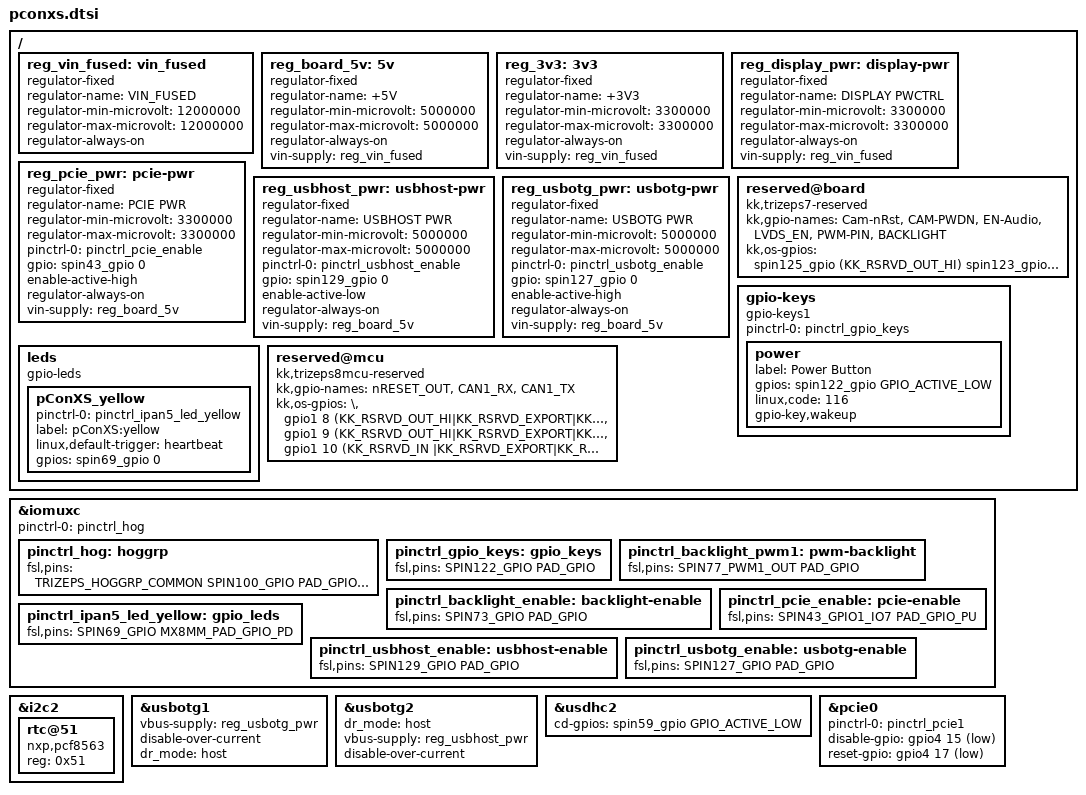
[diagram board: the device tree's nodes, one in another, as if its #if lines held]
/*
 * Copyright 2020 Keith & Koep GmbH
 *
 */

/*
Remarks:
    The main device-tree difference between pConXS V1 and V2 is, that pConXS features:
    - a switch to enable pcie-power
    - 1GBit Ethernet. Use ETHERNET_ONLY_100MBIT define for pConXS V1!

Defines:
    PCONXS_NOT_USE_PCIE_PWR         SPIN113 is used on pConXS V2 to switch power. Since this pin is not connected on V1 no need to actually set this.
	PCONXS_V1 on pConXS V1 pcie-power can not be switched separately but
	          3V3_AUX can be switched by SPIN43 aka. GPIO1_OI7
*/

#define NOBACKLIGHT_PWM         1

&iomuxc {

	pinctrl-names = "default";
	pinctrl-0 = <&pinctrl_hog>;

        pinctrl_hog: hoggrp {
		fsl,pins = < 
					 TRIZEPS_HOGGRP_COMMON
					 SPIN100_GPIO           PAD_GPIO_PU   /* LVDS    EN  SODIMM Pin 110 gpio 1.05=005 */
					 SPIN102_GPIO  		PAD_GPIO_PU   /* Audio Amp                                */
		    		         SPIN123_GPIO		PAD_GPIO_PU   /* Camera Pwdn SODIMM Pin 123               */
   					 SPIN125_GPIO		PAD_GPIO_PU   /* Camera nRST SODIMM Pin 125               */
   					 SPIN114_GPIO		PAD_GPIO_PU   /* BL EN(LVDS) SODIMM Pin 114 gpio 4.14=110 */
#ifndef NOBACKLIGHT_PWM					 
					 SPIN77_GPIO             PAD_GPIO_PU   /* Gpio PWM */
#endif					 
		       >;
	};

#if !defined (__DTS_TRIZEPS8NANO_PINFUNC_H)
        pinctrl_gpio_keys: gpio_keys {
		fsl,pins = < SPIN122_GPIO       PAD_GPIO >;  /* PowerButton SODIMM Pin 122 */
	};
#endif        

#ifndef NOBACKLIGHT
	pinctrl_backlight_pwm1: pwm-backlight {
		fsl,pins = < SPIN77_PWM1_OUT	PAD_GPIO >;	/* BACKLIGHT_PWM */
	};
#endif

	pinctrl_backlight_enable: backlight-enable {
		fsl,pins = < SPIN73_GPIO	    PAD_GPIO 	/* BACKLIGHT_ENABLE SODIMM Pin 73 */
			   >;
#if 0
                             SPIN114 for LVDS Backlight init via HOG 
/* 		             SPIN114_GPIO           PAD_GPIO_PU /* BACKLIGHT_ENABLE SODIMM Pin 114 gpio 4.14=110 */
#endif			   
	};

#if 1 //!defined (PCONXS_NOT_USE_PCIE_PWR) || (PCONXS_NOT_USE_PCIE_PWR==0)
	pinctrl_pcie_enable: pcie-enable 	{
#ifdef PCONXS_V1
		fsl,pins = < SPIN43_GPIO1_IO7   PAD_GPIO_PU >;
#else
		fsl,pins = < SPIN113_GPIO       PAD_GPIO_PU >; /* USBH_PWR SODIMM Pin 113 */
#endif
	};
#endif

	pinctrl_ipan5_led_yellow: gpio_leds
	{
		fsl,pins = <SPIN69_GPIO MX8MM_PAD_GPIO_PD>;  /* Heartbeat LED gpio5.2 SODIMM Pin 69 J12-9 */
	};

	pinctrl_usbhost_enable: usbhost-enable 	{
		fsl,pins = < SPIN129_GPIO		PAD_GPIO >; /* USBH_PWR */
	};

	pinctrl_usbotg_enable: usbotg-enable 	{
		fsl,pins = < SPIN127_GPIO		PAD_GPIO >; /* USBOTG_PWR */
	};		
};

/ {
	reg_vin_fused: vin_fused {
		compatible = "regulator-fixed";
		regulator-name = "VIN_FUSED";
		regulator-min-microvolt = <12000000>;
		/* max	should be 24V but the fixed regulator driver does
		not allow a range here */
		regulator-max-microvolt = <12000000>;
		regulator-always-on;
	};

	reg_board_5v: 5v {
		compatible = "regulator-fixed";
		regulator-name = "+5V";
		regulator-min-microvolt = <5000000>;
		regulator-max-microvolt = <5000000>;
		regulator-always-on;
		vin-supply = <&reg_vin_fused>;
	};

	reg_3v3: 3v3 {
		compatible = "regulator-fixed";
		regulator-name = "+3V3";
		regulator-min-microvolt = <3300000>;
		regulator-max-microvolt = <3300000>;
		regulator-always-on;
		vin-supply = <&reg_vin_fused>;
	};

    reg_display_pwr: display-pwr {
		compatible = "regulator-fixed";
		regulator-name = "DISPLAY PWCTRL";
		regulator-min-microvolt = <3300000>;
		regulator-max-microvolt = <3300000>;
		regulator-always-on;
		vin-supply = <&reg_vin_fused>;
	};

#if 1 //!defined (PCONXS_NOT_USE_PCIE_PWR) || (PCONXS_NOT_USE_PCIE_PWR==0)
	reg_pcie_pwr: pcie-pwr {
		compatible = "regulator-fixed";
		regulator-name = "PCIE PWR";
		regulator-min-microvolt = <3300000>;
		regulator-max-microvolt = <3300000>;
		pinctrl-names = "default";
		pinctrl-0 = <&pinctrl_pcie_enable>;
#ifdef PCONXS_V1
		gpio = <spin43_gpio 0>;
#else
		gpio = <spin113_gpio 0>;
#endif    
		enable-active-high;
		regulator-always-on;
		vin-supply = <&reg_board_5v>;
	};
#endif    

	reg_usbhost_pwr: usbhost-pwr {
		compatible = "regulator-fixed";
		regulator-name = "USBHOST PWR";
		regulator-min-microvolt = <5000000>;
		regulator-max-microvolt = <5000000>;
		pinctrl-names = "default";
		pinctrl-0 = <&pinctrl_usbhost_enable>;
		gpio = <spin129_gpio 0>;
		enable-active-low;
		regulator-always-on;
		vin-supply = <&reg_board_5v>;
	};

	reg_usbotg_pwr: usbotg-pwr {
		compatible = "regulator-fixed";
		regulator-name = "USBOTG PWR";
		regulator-min-microvolt = <5000000>;
		regulator-max-microvolt = <5000000>;
		pinctrl-names = "default";
		pinctrl-0 = <&pinctrl_usbotg_enable>;
		gpio = <spin127_gpio 0>;
#if defined(PCONXS_III_OTG_ACTIVE_HIGH) && (PCONXS_III_OTG_ACTIVE_HIGH==1)
		enable-active-high;
#else
		enable-active-low;
#endif
		regulator-always-on;
		vin-supply = <&reg_board_5v>;
	};

  	reserved@board {
        compatible      = "kk,trizeps7-reserved";
#if NOBACKLIGHT_PWM			    	
        kk,gpio-names   = "Cam-nRst","CAM-PWDN","EN-Audio","LVDS_EN", "PWM-PIN", "BACKLIGHT";
#else
        kk,gpio-names   = "Cam-nRst","CAM-PWDN","EN-Audio","LVDS_EN";
#endif
        kk,os-gpios     = < 
                            spin125_gpio   (KK_RSRVD_OUT_HI)                                     /* Cam-nRST  gpio1 6   */
                            spin123_gpio   (KK_RSRVD_OUT_HI)                                     /* Cam-PWDN  gpio1 3   */
                            spin102_gpio   (KK_RSRVD_OUT_LO|KK_RSRVD_EXPORT|KK_RSRVD_REQUEST(0)) /* Audio En  gpio1 8   */
                            spin100_gpio   (KK_RSRVD_OUT_HI|KK_RSRVD_EXPORT|KK_RSRVD_REQUEST(1)) /* LVDS_EN   gpio1 5   */
#if NOBACKLIGHT_PWM			    
                            spin77_gpio    (KK_RSRVD_OUT_HI|KK_RSRVD_EXPORT|KK_RSRVD_REQUEST(2)) /* PWM Backl gpio1 1   */
			    spin114_gpio   (KK_RSRVD_OUT_HI|KK_RSRVD_EXPORT|KK_RSRVD_REQUEST(3)) /* Backlight gpio4 14  */
#endif			    
                            >;
    };

#if !defined (__DTS_TRIZEPS8NANO_PINFUNC_H)
	gpio-keys {
        compatible = "gpio-keys1";
        pinctrl-names = "default";
        pinctrl-0 = <&pinctrl_gpio_keys>;
        power { /* Reconfig to power key in Android*/
            label = "Power Button";
            gpios = <spin122_gpio GPIO_ACTIVE_LOW>;
            linux,code = <116>; /* KEY_POWER */
            gpio-key,wakeup;
          };
        };

	leds {
		compatible = "gpio-leds";
		pConXS_yellow {
			pinctrl-names = "default";
			pinctrl-0     = <&pinctrl_ipan5_led_yellow>;
			label         = "pConXS:yellow";
			linux,default-trigger = "heartbeat";
			gpios         = <spin69_gpio 0>; /* Gpio 5 2 */
		};
	};
#endif    
};

#ifndef NOBACKLIGHT_PWM
&pwm1 {
	pinctrl-names = "default";
	pinctrl-0 = <&pinctrl_backlight_pwm1>;	
	status = "okay";
};


&backlight {
	status = "okay";
	pinctrl-0 = <&pinctrl_backlight_enable>;
#if defined(PRIMARY_DISPLAY_LVDS) && (PRIMARY_DISPLAY_LVDS==1)
	enable-gpios = <spin114_gpio GPIO_ACTIVE_HIGH>;
#else
	enable-gpios = <spin73_gpio GPIO_ACTIVE_HIGH>;
#endif	
	brightness-levels = < 100 
				99 98 97 96 95 94 93 92 91 90
				89 88 87 86 85 84 83 82 81 80
				79 78 77 76 75 74 73 72 71 70
				69 68 67 66 65 64 63 62 61 60
				59 58 57 56 55 54 53 52 51 50
				49 48 47 46 45 44 43 42 41 40
				39 38 37 36 35 34 33 32 31 30
				29 28 27 26 25 24 23 22 21 20
				19 18 17 16 15 14 13 12 11 10
				 9  8  7  6  5  4  3  2  1  0>;    
};
#endif

&i2c2 {
	rtc@51 {
		compatible = "nxp,pcf8563";
		reg = <0x51>;
	};
};

#if !defined (__DTS_IMX8MQ_PINFUNC_H)

&usbotg1 {
	vbus-supply = <&reg_usbotg_pwr>; 
	disable-over-current;
 #if  defined(USB1_OTG_FUNC) && (USB1_OTG_FUNC==OTG_HOST)
	dr_mode = "host";
 #else
  #if defined(USB1_OTG_FUNC) && (USB1_OTG_FUNC==OTG_FUNC)
	dr_mode = "otg";
  #else
        dr_mode = "peripheral";
  #endif
 #endif
};

#if !defined (__DTS_IMX8MN_PINFUNC_H)
&usbotg2 {
	dr_mode = "host";
	vbus-supply = <&reg_usbhost_pwr>; 
	disable-over-current; 
};
#endif
#endif

&usdhc2 {
	cd-gpios = <spin59_gpio GPIO_ACTIVE_LOW>;
	status = "okay";	
};

#if 0
&wm8983 {
	mute-gpios = <spin102_gpio GPIO_ACTIVE_HIGH>; /* Works but leads to "plops" */
};
#endif


/************************************************************************/
#if defined (__DTS_TRIZEPS8_PINFUNC_H) || defined (__DTS_TRIZEPS8MINI_PINFUNC_H) || defined (__DTS_TRIZEPS8NANO_PINFUNC_H)
/ {
	reserved@mcu{
		compatible     = "kk,trizeps8mcu-reserved";
        kk,gpio-names  = "nRESET_OUT", "CAN1_RX", "CAN1_TX";
        /* gpio1 -- 0:AD3, 1:AD2, 2:AD1, 3:AD0, 4:TSPX, 5:TSMX, 6:TSPY, 7:TSMY, 8:RESET_OUT, 9:CAN1_RX, 10:CAN1_TX */
        kk,os-gpios = <\
                		&gpio1  8 (KK_RSRVD_OUT_HI|KK_RSRVD_EXPORT|KK_RSRVD_REQUEST(0)) /* RESET_OUT */
			        &gpio1  9 (KK_RSRVD_OUT_HI|KK_RSRVD_EXPORT|KK_RSRVD_REQUEST(1)) /* CAN1_RX */
			        &gpio1 10 (KK_RSRVD_IN    |KK_RSRVD_EXPORT|KK_RSRVD_REQUEST(2)) /* CAN1_TX */
                    >;
    };	
};

&pcie0{
	pinctrl-0     = <&pinctrl_pcie1>;
	disable-gpio  = <&gpio4 15 GPIO_ACTIVE_LOW>;
	reset-gpio    = <&gpio4 17 GPIO_ACTIVE_LOW>;
};

#endif

